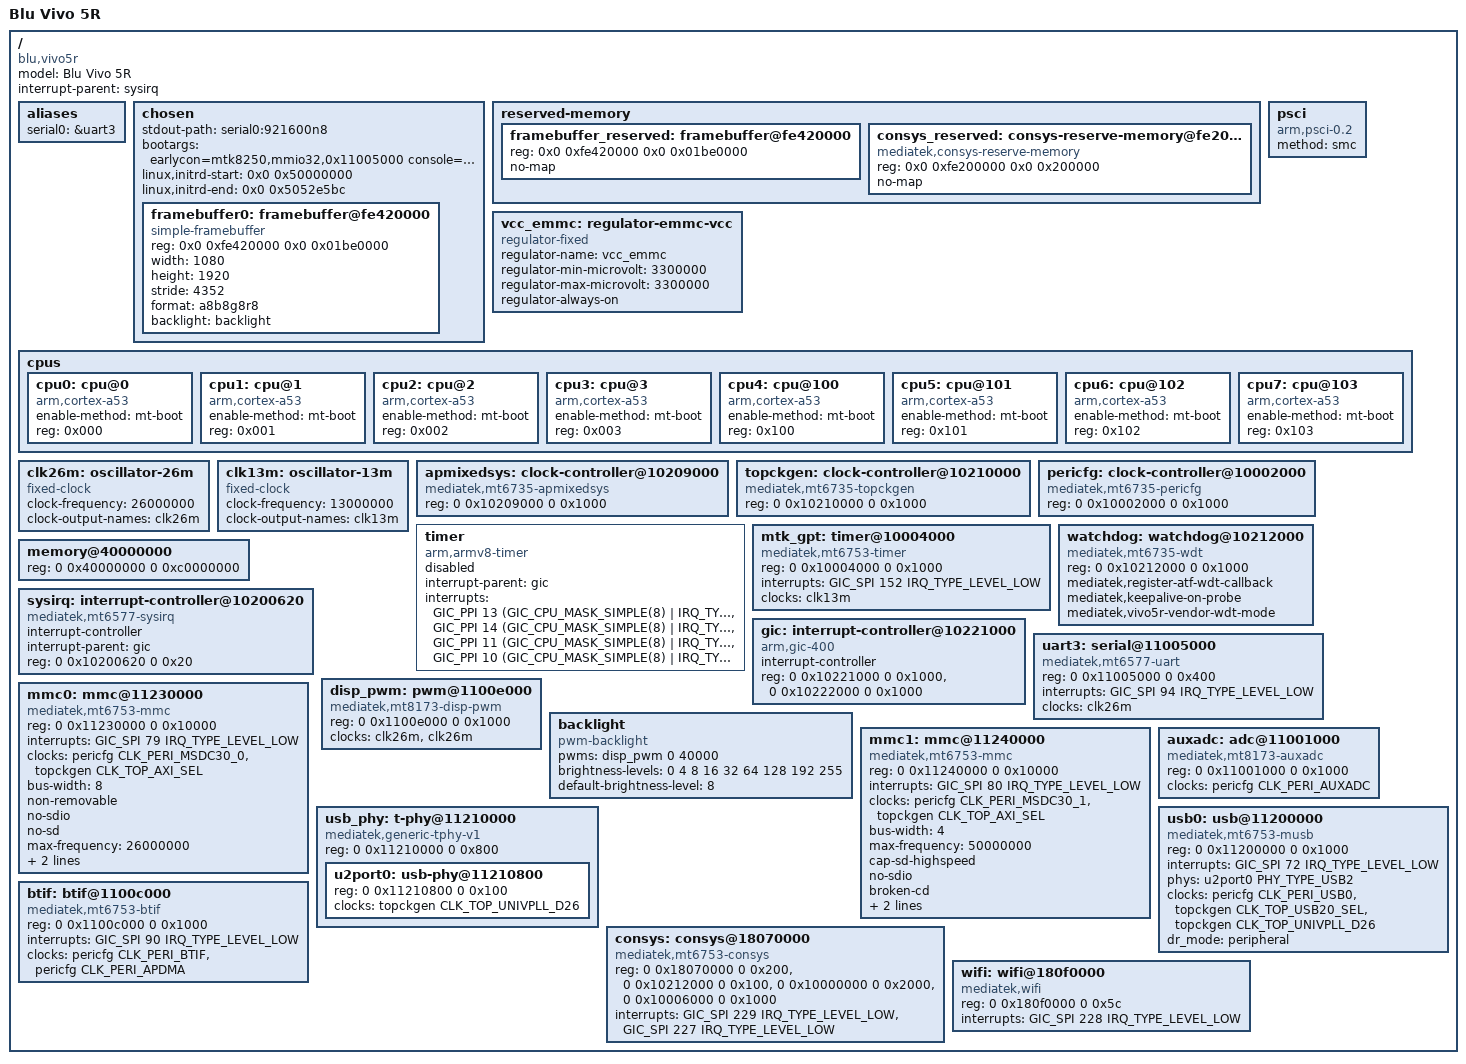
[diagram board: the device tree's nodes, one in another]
// SPDX-License-Identifier: GPL-2.0-only
/*
 * Minimal first-stage board description for the Blu Vivo 5R.
 *
 * This is intentionally limited to the CPU, interrupt controller, timer,
 * memory and diagnostic UART.  Peripheral blocks will be added only after
 * this description has been validated on the device.
 */

/dts-v1/;

#include <dt-bindings/interrupt-controller/arm-gic.h>
#include <dt-bindings/interrupt-controller/irq.h>
#include <dt-bindings/clock/mediatek,mt6735-pericfg.h>
#include <dt-bindings/clock/mediatek,mt6735-topckgen.h>
#include <dt-bindings/phy/phy.h>

/ {
	model = "Blu Vivo 5R";
	compatible = "blu,vivo5r", "mediatek,mt6753";

	#address-cells = <2>;
	#size-cells = <2>;
	interrupt-parent = <&sysirq>;

	aliases {
		serial0 = &uart3;
	};

	chosen {
		stdout-path = "serial0:921600n8";
		bootargs = "earlycon=mtk8250,mmio32,0x11005000 console=ttyS0,921600n8 loglevel=4 slub_debug=- clk_ignore_unused selinux=0 user_debug=31 irqchip.gicv2_force_probe=1 maxcpus=4 clocksource=timer@10004000 bootopt=64S3,32N2,64N2 printk.disable_uart=0";
		linux,initrd-start = <0x0 0x50000000>;
		linux,initrd-end = <0x0 0x5052e5bc>;

		#address-cells = <2>;
		#size-cells = <2>;
		ranges;

		framebuffer0: framebuffer@fe420000 {
			compatible = "simple-framebuffer";
			reg = <0x0 0xfe420000 0x0 0x01be0000>;
			width = <1080>;
			height = <1920>;
			stride = <4352>;
			format = "a8b8g8r8";
			backlight = <&backlight>;
		};
	};

	reserved-memory {
		#address-cells = <2>;
		#size-cells = <2>;
		ranges;

		framebuffer_reserved: framebuffer@fe420000 {
			reg = <0x0 0xfe420000 0x0 0x01be0000>;
			no-map;
		};

		consys_reserved: consys-reserve-memory@fe200000 {
			compatible = "mediatek,consys-reserve-memory";
			reg = <0x0 0xfe200000 0x0 0x200000>;
			no-map;
		};
	};

	vcc_emmc: regulator-emmc-vcc {
		compatible = "regulator-fixed";
		regulator-name = "vcc_emmc";
		regulator-min-microvolt = <3300000>;
		regulator-max-microvolt = <3300000>;
		regulator-always-on;
	};

	psci {
		compatible = "arm,psci-0.2";
		method = "smc";
	};

	cpus {
		#address-cells = <1>;
		#size-cells = <0>;

		cpu0: cpu@0 {
			device_type = "cpu";
			compatible = "arm,cortex-a53";
			enable-method = "mt-boot";
			reg = <0x000>;
		};

		cpu1: cpu@1 {
			device_type = "cpu";
			compatible = "arm,cortex-a53";
			enable-method = "mt-boot";
			reg = <0x001>;
		};

		cpu2: cpu@2 {
			device_type = "cpu";
			compatible = "arm,cortex-a53";
			enable-method = "mt-boot";
			reg = <0x002>;
		};

		cpu3: cpu@3 {
			device_type = "cpu";
			compatible = "arm,cortex-a53";
			enable-method = "mt-boot";
			reg = <0x003>;
		};

		cpu4: cpu@100 {
			device_type = "cpu";
			compatible = "arm,cortex-a53";
			enable-method = "mt-boot";
			reg = <0x100>;
		};

		cpu5: cpu@101 {
			device_type = "cpu";
			compatible = "arm,cortex-a53";
			enable-method = "mt-boot";
			reg = <0x101>;
		};

		cpu6: cpu@102 {
			device_type = "cpu";
			compatible = "arm,cortex-a53";
			enable-method = "mt-boot";
			reg = <0x102>;
		};

		cpu7: cpu@103 {
			device_type = "cpu";
			compatible = "arm,cortex-a53";
			enable-method = "mt-boot";
			reg = <0x103>;
		};
	};

	clk26m: oscillator-26m {
		compatible = "fixed-clock";
		#clock-cells = <0>;
		clock-frequency = <26000000>;
		clock-output-names = "clk26m";
	};

	clk13m: oscillator-13m {
		compatible = "fixed-clock";
		#clock-cells = <0>;
		clock-frequency = <13000000>;
		clock-output-names = "clk13m";
	};

	apmixedsys: clock-controller@10209000 {
		compatible = "mediatek,mt6735-apmixedsys";
		reg = <0 0x10209000 0 0x1000>;
		#clock-cells = <1>;
	};

	topckgen: clock-controller@10210000 {
		compatible = "mediatek,mt6735-topckgen", "syscon";
		reg = <0 0x10210000 0 0x1000>;
		#clock-cells = <1>;
	};

	pericfg: clock-controller@10002000 {
		compatible = "mediatek,mt6735-pericfg", "syscon";
		reg = <0 0x10002000 0 0x1000>;
		#clock-cells = <1>;
	};

	timer {
		compatible = "arm,armv8-timer";
		status = "disabled";
		interrupt-parent = <&gic>;
		interrupts = <GIC_PPI 13
				     (GIC_CPU_MASK_SIMPLE(8) | IRQ_TYPE_LEVEL_LOW)>,
				    <GIC_PPI 14
				     (GIC_CPU_MASK_SIMPLE(8) | IRQ_TYPE_LEVEL_LOW)>,
				    <GIC_PPI 11
				     (GIC_CPU_MASK_SIMPLE(8) | IRQ_TYPE_LEVEL_LOW)>,
				    <GIC_PPI 10
				     (GIC_CPU_MASK_SIMPLE(8) | IRQ_TYPE_LEVEL_LOW)>;
	};

	mtk_gpt: timer@10004000 {
		compatible = "mediatek,mt6753-timer";
		reg = <0 0x10004000 0 0x1000>;
		interrupts = <GIC_SPI 152 IRQ_TYPE_LEVEL_LOW>;
		clocks = <&clk13m>;
		clock-names = "timer";
	};

	watchdog: watchdog@10212000 {
		compatible = "mediatek,mt6735-wdt";
		reg = <0 0x10212000 0 0x1000>;
		mediatek,register-atf-wdt-callback;
		mediatek,keepalive-on-probe;
		mediatek,vivo5r-vendor-wdt-mode;
	};

	memory@40000000 {
		device_type = "memory";
		reg = <0 0x40000000 0 0xc0000000>;
	};

	sysirq: interrupt-controller@10200620 {
		compatible = "mediatek,mt6577-sysirq";
		interrupt-controller;
		#interrupt-cells = <3>;
		interrupt-parent = <&gic>;
		reg = <0 0x10200620 0 0x20>;
	};

	gic: interrupt-controller@10221000 {
		compatible = "arm,gic-400";
		#interrupt-cells = <3>;
		interrupt-controller;
		reg = <0 0x10221000 0 0x1000>,
		      <0 0x10222000 0 0x1000>;
	};

	uart3: serial@11005000 {
		compatible = "mediatek,mt6577-uart";
		reg = <0 0x11005000 0 0x400>;
		interrupts = <GIC_SPI 94 IRQ_TYPE_LEVEL_LOW>;
		clocks = <&clk26m>;
		status = "okay";
	};

	disp_pwm: pwm@1100e000 {
		compatible = "mediatek,mt8173-disp-pwm";
		reg = <0 0x1100e000 0 0x1000>;
		#pwm-cells = <2>;
		clocks = <&clk26m>, <&clk26m>;
		clock-names = "main", "mm";
		status = "okay";
	};

	backlight: backlight {
		compatible = "pwm-backlight";
		pwms = <&disp_pwm 0 40000>;
		brightness-levels = <0 4 8 16 32 64 128 192 255>;
		default-brightness-level = <8>;
		status = "okay";
	};

	mmc0: mmc@11230000 {
		compatible = "mediatek,mt6753-mmc";
		reg = <0 0x11230000 0 0x10000>;
		interrupts = <GIC_SPI 79 IRQ_TYPE_LEVEL_LOW>;
		clocks = <&pericfg CLK_PERI_MSDC30_0>,
			 <&topckgen CLK_TOP_AXI_SEL>;
		clock-names = "source", "hclk";
		bus-width = <8>;
		non-removable;
		no-sdio;
		no-sd;
		max-frequency = <26000000>;
		vmmc-supply = <&vcc_emmc>;
		mediatek,no-pinctrl;
		status = "okay";
	};

	mmc1: mmc@11240000 {
		compatible = "mediatek,mt6753-mmc";
		reg = <0 0x11240000 0 0x10000>;
		interrupts = <GIC_SPI 80 IRQ_TYPE_LEVEL_LOW>;
		clocks = <&pericfg CLK_PERI_MSDC30_1>,
			 <&topckgen CLK_TOP_AXI_SEL>;
		clock-names = "source", "hclk";
		bus-width = <4>;
		max-frequency = <50000000>;
		cap-sd-highspeed;
		no-sdio;
		broken-cd;
		vmmc-supply = <&vcc_emmc>;
		mediatek,no-pinctrl;
		status = "okay";
	};

	auxadc: adc@11001000 {
		compatible = "mediatek,mt8173-auxadc";
		reg = <0 0x11001000 0 0x1000>;
		clocks = <&pericfg CLK_PERI_AUXADC>;
		clock-names = "main";
		#io-channel-cells = <1>;
		status = "okay";
	};

	usb_phy: t-phy@11210000 {
		compatible = "mediatek,generic-tphy-v1";
		reg = <0 0x11210000 0 0x800>;
		#address-cells = <2>;
		#size-cells = <2>;
		ranges;
		status = "okay";

		u2port0: usb-phy@11210800 {
			reg = <0 0x11210800 0 0x100>;
			clocks = <&topckgen CLK_TOP_UNIVPLL_D26>;
			clock-names = "ref";
			#phy-cells = <1>;
			status = "okay";
		};
	};

	usb0: usb@11200000 {
		compatible = "mediatek,mt6753-musb", "mediatek,mtk-musb";
		reg = <0 0x11200000 0 0x1000>;
		interrupts = <GIC_SPI 72 IRQ_TYPE_LEVEL_LOW>;
		interrupt-names = "mc";
		phys = <&u2port0 PHY_TYPE_USB2>;
		clocks = <&pericfg CLK_PERI_USB0>,
			 <&topckgen CLK_TOP_USB20_SEL>,
			 <&topckgen CLK_TOP_UNIVPLL_D26>;
		clock-names = "main", "mcu", "univpll";
		dr_mode = "peripheral";
		status = "okay";
	};

	btif: btif@1100c000 {
		compatible = "mediatek,mt6753-btif", "mediatek,mt6735-btif", "mediatek,btif";
		reg = <0 0x1100c000 0 0x1000>;
		interrupts = <GIC_SPI 90 IRQ_TYPE_LEVEL_LOW>;
		clocks = <&pericfg CLK_PERI_BTIF>,
			 <&pericfg CLK_PERI_APDMA>;
		clock-names = "btifc", "apdmac";
		status = "okay";
	};

	consys: consys@18070000 {
		compatible = "mediatek,mt6753-consys", "mediatek,mt6735-consys";
		reg = <0 0x18070000 0 0x200>,
		      <0 0x10212000 0 0x100>,
		      <0 0x10000000 0 0x2000>,
		      <0 0x10006000 0 0x1000>;
		interrupts = <GIC_SPI 229 IRQ_TYPE_LEVEL_LOW>,
		             <GIC_SPI 227 IRQ_TYPE_LEVEL_LOW>;
		status = "okay";
	};

	wifi: wifi@180f0000 {
		compatible = "mediatek,wifi";
		reg = <0 0x180f0000 0 0x5c>;
		interrupts = <GIC_SPI 228 IRQ_TYPE_LEVEL_LOW>;
		status = "okay";
	};
};
